# soc register map
File version: 1.0
Esimerkkipiiri
Registers are 32-bit, read-write, reset 0x0 unless marked. A register's access mark holds for its fields unless they carry their own. Offsets are from the block's base; lines under a group give offsets from that group; [hi:lo] are bit positions; {n}, {i} and the like mark numbered series; 'fields as' and 'values as' point back to an identical list; <NAME> marks a mode.

## Memory map
0x40001000 AJASTIN0 size 0x10 — Ajastin
0x40001100 AJASTIN1 size 0x10
0x40002000 DMA0 size 0x120 — DMA-ohjain

## Interrupts
3 AJASTIN0_IRQ (AJASTIN0)
4 AJASTIN1_IRQ (AJASTIN1)
7 DMA0_IRQ (DMA0)

## AJASTIN0 — Ajastin
Base 0x40001000
Same registers: AJASTIN1 0x40001100
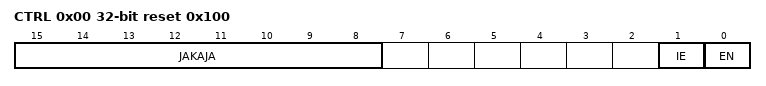
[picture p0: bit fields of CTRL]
0x00 CTRL reset 0x100 — Ohjaus
  [15:8] JAKAJA — Kellon jakaja.
  [1] IE — Keskeytys sallittu.
  [0] EN — Ajastin kay.
0x04 STATUS — Tila
  [0] VALMIS write-1-clears — Vertailuarvo saavutettu. 1 nollaa.
0x08 LASKURI — Laskurin arvo
  [15:0] ARVO ro — Nykyinen arvo.
0x0C VERTAA reset 0xFFFF — Vertailuarvo
  [15:0] ARVO — Arvo, jolla VALMIS asettuu.

## DMA0 — DMA-ohjain
Base 0x40002000
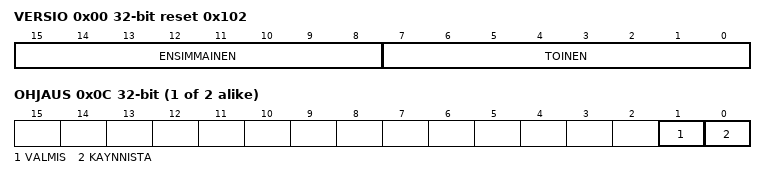
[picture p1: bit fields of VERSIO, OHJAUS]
0x00 VERSIO reset 0x102
  [15:8] ENSIMMAINEN ro, [7:0] TOINEN ro
0x04 SUOJAUS — Suojattu tila
  [0] LUKITUS — Vain suojattu ohjelmisto saa muuttaa.
{0x100+0x10*i} KANAVA[{i}] (i=0..1) group
  0x00 LAHDE
    [31:0] OSOITE
  0x04 KOHDE
    [31:0] OSOITE
  0x08 PITUUS
    [23:0] TAVUJA
  0x0C OHJAUS
    [1] VALMIS ro, [0] KAYNNISTA
